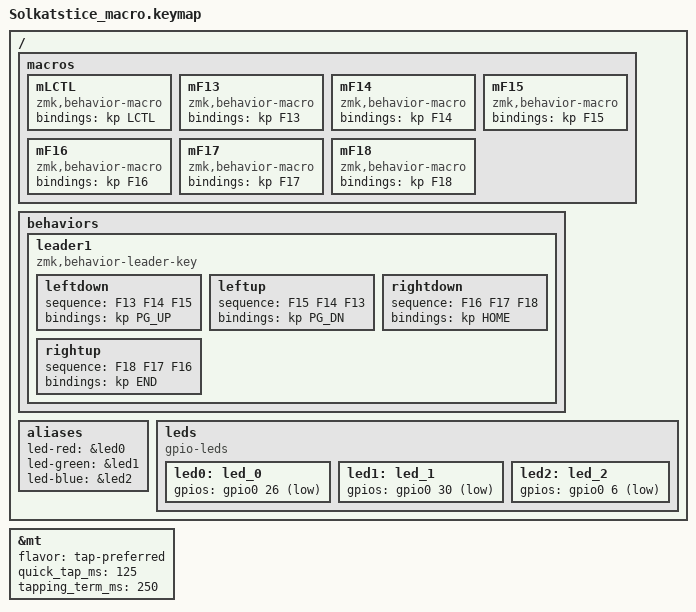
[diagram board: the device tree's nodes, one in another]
&mt {
   flavor = "tap-preferred";
   quick_tap_ms = <125>;
   tapping_term_ms = <250>;
};

/ {
    macros {
        mLCTL: mLCTL {
            compatible = "zmk,behavior-macro";
            #binding-cells = <0>;
            bindings = <&kp LCTL>;
        };
        mF13: mF13 {
            compatible = "zmk,behavior-macro";
            #binding-cells = <0>;
            bindings = <&kp F13>;
        };
        mF14: mF14 {
            compatible = "zmk,behavior-macro";
            #binding-cells = <0>;
            bindings = <&kp F14>;
        };
        mF15: mF15 {
            compatible = "zmk,behavior-macro";
            #binding-cells = <0>;
            bindings = <&kp F15>;
        };
        mF16: mF16 {
            compatible = "zmk,behavior-macro";
            #binding-cells = <0>;
            bindings = <&kp F16>;
        };
        mF17: mF17 {
            compatible = "zmk,behavior-macro";
            #binding-cells = <0>;
            bindings = <&kp F17>;
        };
        mF18: mF18 {
            compatible = "zmk,behavior-macro";
            #binding-cells = <0>;
            bindings = <&kp F18>;
        };
    };

    behaviors {
        leader1: leader1 {
            compatible = "zmk,behavior-leader-key";
            #binding-cells = <0>;
            leftdown { sequence = <F13 F14 F15>; bindings = <&kp PG_UP>; };
            leftup   { sequence = <F15 F14 F13>; bindings = <&kp PG_DN>; };
            rightdown { sequence = <F16 F17 F18>; bindings = <&kp HOME>; };
            rightup   { sequence = <F18 F17 F16>; bindings = <&kp END>; };
        };
    }; 
}; 
 
/ {
    aliases {
        led-red = &led0;
        led-green = &led1;
        led-blue = &led2;
    };

    leds {
        compatible = "gpio-leds";
        status = "okay";
        led0: led_0 {
            gpios = <&gpio0 26 GPIO_ACTIVE_LOW>;  // red LED, connected to P0.26
        };
        led1: led_1 {
            gpios = <&gpio0 30 GPIO_ACTIVE_LOW>;  // green LED, connected to P0.30
        };
        led2: led_2 {
            gpios = <&gpio0 6 GPIO_ACTIVE_LOW>;  // blue LED, connected to P0.06
        };
    };
};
